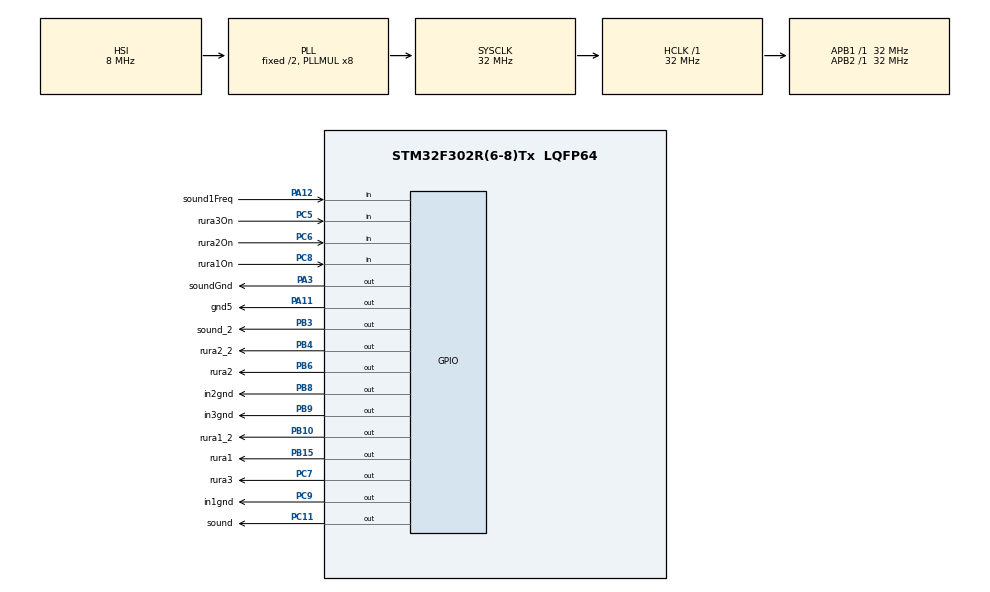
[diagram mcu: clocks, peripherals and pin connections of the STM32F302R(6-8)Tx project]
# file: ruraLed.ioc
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Mcu.Family=STM32F3
Mcu.Name=STM32F302R(6-8)Tx
Mcu.Package=LQFP64
NVIC.PriorityGroup=NVIC_PRIORITYGROUP_4
PA11.GPIO_Label=gnd5
PA11.Signal=GPIO_Output
PA12.GPIO_Label=sound1Freq
PA12.GPIO_PuPd=GPIO_PULLUP
PA12.Signal=GPIO_Input
PA3.GPIO_Label=soundGnd
PA3.Signal=GPIO_Output
PB10.GPIO_Label=rura1_2
PB10.Signal=GPIO_Output
PB15.GPIO_Label=rura1
PB15.Signal=GPIO_Output
PB3.GPIO_Label=sound_2
PB3.GPIO_Speed=GPIO_SPEED_FREQ_LOW
PB3.Signal=GPIO_Output
PB4.GPIO_Label=rura2_2
PB4.Signal=GPIO_Output
PB6.GPIO_Label=rura2
PB6.Signal=GPIO_Output
PB8.GPIO_Label=in2gnd
PB8.GPIO_PuPd=GPIO_NOPULL
PB8.Signal=GPIO_Output
PB9.GPIO_Label=in3gnd
PB9.Signal=GPIO_Output
PC11.GPIO_Label=sound
PC11.Signal=GPIO_Output
PC5.GPIO_Label=rura3On
PC5.GPIO_PuPd=GPIO_PULLUP
PC5.Signal=GPIO_Input
PC6.GPIO_Label=rura2On
PC6.GPIO_PuPd=GPIO_PULLUP
PC6.Signal=GPIO_Input
PC7.GPIO_Label=rura3
PC7.Signal=GPIO_Output
PC8.GPIO_Label=rura1On
PC8.GPIO_PuPd=GPIO_PULLUP
PC8.Signal=GPIO_Input
PC9.GPIO_Label=in1gnd
PC9.Signal=GPIO_Output
ProjectManager.HeapSize=0x200
ProjectManager.StackSize=0x400
ProjectManager.TargetToolchain=STM32CubeIDE
RCC.AHBFreq_Value=32000000
RCC.APB1Freq_Value=32000000
RCC.APB1TimFreq_Value=32000000
RCC.APB2Freq_Value=32000000
RCC.APB2TimFreq_Value=32000000
RCC.CortexFreq_Value=32000000
RCC.HCLKFreq_Value=32000000
RCC.HSE_VALUE=8000000
RCC.HSI_VALUE=8000000
RCC.LSE_VALUE=32768
RCC.PLLMUL=RCC_PLL_MUL8
RCC.SYSCLKFreq_VALUE=32000000
RCC.SYSCLKSourceVirtual=RCC_SYSCLKSOURCE_PLLCLK
RCC.USBFreq_Value=32000000
board=custom

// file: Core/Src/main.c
/* USER CODE BEGIN Header */
/**
  ******************************************************************************
  * @file           : main.c
  * @brief          : Main program body
  ******************************************************************************
  * @attention
  *
  * Copyright (c) 2024 STMicroelectronics.
  * All rights reserved.
  *
  * This software is licensed under terms that can be found in the LICENSE file
  * in the root directory of this software component.
  * If no LICENSE file comes with this software, it is provided AS-IS.
  *
  ******************************************************************************
  */
/* USER CODE END Header */
#include "main.h"

/* USER CODE BEGIN Includes */

#include "mainFunctions.h"

/* USER CODE END Includes */

void SystemClock_Config(void);
static void MX_GPIO_Init(void);

int main(void)
{

  /* MCU Configuration--------------------------------------------------------*/

  /* Reset of all peripherals, Initializes the Flash interface and the Systick. */
  HAL_Init();

  /* Configure the system clock */
  SystemClock_Config();

  /* Initialize all configured peripherals */
  MX_GPIO_Init();
  /* USER CODE BEGIN 2 */

  userInit();

  /* USER CODE END 2 */

  /* Infinite loop */
  while (1)
  {

    /* USER CODE BEGIN 3 */
	  mainPoll();
  }
  /* USER CODE END 3 */
}

void SystemClock_Config(void)
{
  RCC_OscInitTypeDef RCC_OscInitStruct = {0};
  RCC_ClkInitTypeDef RCC_ClkInitStruct = {0};

  /** Initializes the RCC Oscillators according to the specified parameters
  * in the RCC_OscInitTypeDef structure.
  */
  RCC_OscInitStruct.OscillatorType = RCC_OSCILLATORTYPE_HSI;
  RCC_OscInitStruct.HSIState = RCC_HSI_ON;
  RCC_OscInitStruct.HSICalibrationValue = RCC_HSICALIBRATION_DEFAULT;
  RCC_OscInitStruct.PLL.PLLState = RCC_PLL_ON;
  RCC_OscInitStruct.PLL.PLLSource = RCC_PLLSOURCE_HSI;
  RCC_OscInitStruct.PLL.PLLMUL = RCC_PLL_MUL8;
  if (HAL_RCC_OscConfig(&RCC_OscInitStruct) != HAL_OK)
  {
    Error_Handler();
  }

  /** Initializes the CPU, AHB and APB buses clocks
  */
  RCC_ClkInitStruct.ClockType = RCC_CLOCKTYPE_HCLK|RCC_CLOCKTYPE_SYSCLK
                              |RCC_CLOCKTYPE_PCLK1|RCC_CLOCKTYPE_PCLK2;
  RCC_ClkInitStruct.SYSCLKSource = RCC_SYSCLKSOURCE_PLLCLK;
  RCC_ClkInitStruct.AHBCLKDivider = RCC_SYSCLK_DIV1;
  RCC_ClkInitStruct.APB1CLKDivider = RCC_HCLK_DIV1;
  RCC_ClkInitStruct.APB2CLKDivider = RCC_HCLK_DIV1;

  if (HAL_RCC_ClockConfig(&RCC_ClkInitStruct, FLASH_LATENCY_1) != HAL_OK)
  {
    Error_Handler();
  }
}

static void MX_GPIO_Init(void)
{
  GPIO_InitTypeDef GPIO_InitStruct = {0};

  /* GPIO Ports Clock Enable */
  __HAL_RCC_GPIOA_CLK_ENABLE();
  __HAL_RCC_GPIOC_CLK_ENABLE();
  __HAL_RCC_GPIOB_CLK_ENABLE();

  /*Configure GPIO pin Output Level */
  HAL_GPIO_WritePin(GPIOA, soundGnd_Pin|gnd5_Pin, GPIO_PIN_RESET);

  /*Configure GPIO pin Output Level */
  HAL_GPIO_WritePin(GPIOB, rura1_2_Pin|rura1_Pin|sound_2_Pin|rura2_2_Pin
                          |rura2_Pin|in2gnd_Pin|in3gnd_Pin, GPIO_PIN_RESET);

  /*Configure GPIO pin Output Level */
  HAL_GPIO_WritePin(GPIOC, rura3_Pin|in1gnd_Pin|sound_Pin, GPIO_PIN_RESET);

  /*Configure GPIO pins : soundGnd_Pin gnd5_Pin */
  GPIO_InitStruct.Pin = soundGnd_Pin|gnd5_Pin;
  GPIO_InitStruct.Mode = GPIO_MODE_OUTPUT_PP;
  GPIO_InitStruct.Pull = GPIO_NOPULL;
  GPIO_InitStruct.Speed = GPIO_SPEED_FREQ_LOW;
  HAL_GPIO_Init(GPIOA, &GPIO_InitStruct);

  /*Configure GPIO pins : rura3On_Pin rura2On_Pin rura1On_Pin */
  GPIO_InitStruct.Pin = rura3On_Pin|rura2On_Pin|rura1On_Pin;
  GPIO_InitStruct.Mode = GPIO_MODE_INPUT;
  GPIO_InitStruct.Pull = GPIO_PULLUP;
  HAL_GPIO_Init(GPIOC, &GPIO_InitStruct);

  /*Configure GPIO pins : rura1_2_Pin rura1_Pin sound_2_Pin rura2_2_Pin
                           rura2_Pin in2gnd_Pin in3gnd_Pin */
  GPIO_InitStruct.Pin = rura1_2_Pin|rura1_Pin|sound_2_Pin|rura2_2_Pin
                          |rura2_Pin|in2gnd_Pin|in3gnd_Pin;
  GPIO_InitStruct.Mode = GPIO_MODE_OUTPUT_PP;
  GPIO_InitStruct.Pull = GPIO_NOPULL;
  GPIO_InitStruct.Speed = GPIO_SPEED_FREQ_LOW;
  HAL_GPIO_Init(GPIOB, &GPIO_InitStruct);

  /*Configure GPIO pins : rura3_Pin in1gnd_Pin sound_Pin */
  GPIO_InitStruct.Pin = rura3_Pin|in1gnd_Pin|sound_Pin;
  GPIO_InitStruct.Mode = GPIO_MODE_OUTPUT_PP;
  GPIO_InitStruct.Pull = GPIO_NOPULL;
  GPIO_InitStruct.Speed = GPIO_SPEED_FREQ_LOW;
  HAL_GPIO_Init(GPIOC, &GPIO_InitStruct);

  /*Configure GPIO pin : sound1Freq_Pin */
  GPIO_InitStruct.Pin = sound1Freq_Pin;
  GPIO_InitStruct.Mode = GPIO_MODE_INPUT;
  GPIO_InitStruct.Pull = GPIO_PULLUP;
  HAL_GPIO_Init(sound1Freq_GPIO_Port, &GPIO_InitStruct);

}

void Error_Handler(void)
{
  __disable_irq();
  while (1)
  {
  }
}
